# MSS_CTRL_MSS_CTRL_50D00000h register map
Vendor: Texas Instruments
Registers are 32-bit, read-write, reset values left out (the file's numbers can be read two ways) unless marked. A register's access mark holds for its fields unless they carry their own. Offsets are as the file gives them; [hi:lo] are bit positions; {n}, {i} and the like mark numbered series.

## MSS_CTRL (part 4 of 4)
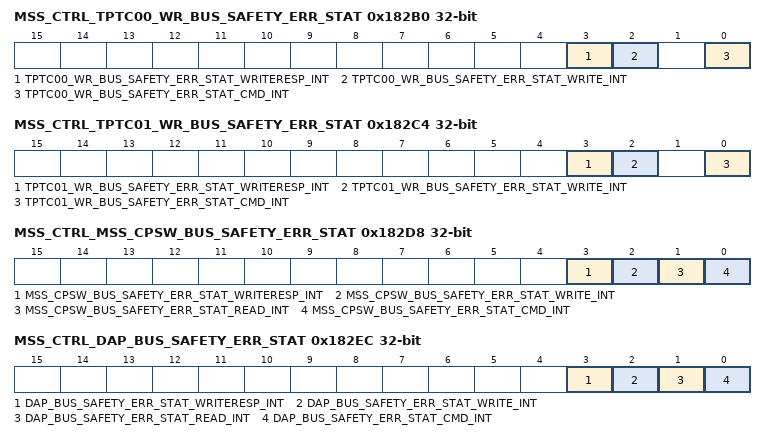
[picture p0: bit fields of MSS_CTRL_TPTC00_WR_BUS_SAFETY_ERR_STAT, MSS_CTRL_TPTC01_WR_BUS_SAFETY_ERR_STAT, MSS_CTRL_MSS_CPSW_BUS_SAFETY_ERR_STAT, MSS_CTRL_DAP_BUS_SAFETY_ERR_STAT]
0x182B0 MSS_CTRL_TPTC00_WR_BUS_SAFETY_ERR_STAT ro — This register Indicates the Error Syndrome of Command errors in Bus Safety Comparator of TPTC00_WR Initiator Port.
  [3] TPTC00_WR_BUS_SAFETY_ERR_STAT_WRITERESP_INT — Read this bitfield for comparator status for Write response bus from interconnect for this port. 1'b1 indicates error on Write Response Bus.
  [2] TPTC00_WR_BUS_SAFETY_ERR_STAT_WRITE_INT — Read this bitfield for comparator status for Write bus from interconnect for this port. 1'b1 at any bit indicates error on Write Bus
  [0] TPTC00_WR_BUS_SAFETY_ERR_STAT_CMD_INT — Read this bitfield for comparator status for command bus for this port. 1'b1 on any of the bits indicates an error on Command Bus
0x182C4 MSS_CTRL_TPTC01_WR_BUS_SAFETY_ERR_STAT ro — This register Indicates the Error Syndrome of Command errors in Bus Safety Comparator of TPTC01_WR Initiator Port.
  [3] TPTC01_WR_BUS_SAFETY_ERR_STAT_WRITERESP_INT — Read this bitfield for comparator status for Write response bus from interconnect for this port. 1'b1 indicates error on Write Response Bus.
  [2] TPTC01_WR_BUS_SAFETY_ERR_STAT_WRITE_INT — Read this bitfield for comparator status for Write bus from interconnect for this port. 1'b1 at any bit indicates error on Write Bus
  [0] TPTC01_WR_BUS_SAFETY_ERR_STAT_CMD_INT — Read this bitfield for comparator status for command bus for this port. 1'b1 on any of the bits indicates an error on Command Bus
0x182D8 MSS_CTRL_MSS_CPSW_BUS_SAFETY_ERR_STAT ro — This register Indicates the Error Syndrome of Command errors in Bus Safety Comparator of CPSW Initiator Port.
  [3] MSS_CPSW_BUS_SAFETY_ERR_STAT_WRITERESP_INT — Read this bitfield for comparator status for Write response bus from interconnect for this port. 1'b1 indicates error on Write Response Bus.
  [2] MSS_CPSW_BUS_SAFETY_ERR_STAT_WRITE_INT — Read this bitfield for comparator status for Write bus from interconnect for this port. 1'b1 at any bit indicates error on Write Bus
  [1] MSS_CPSW_BUS_SAFETY_ERR_STAT_READ_INT — Read this bitfield for comapartor status for read signals at this port. 1'b1 on any of the bits indicates an error on Read bus.
  [0] MSS_CPSW_BUS_SAFETY_ERR_STAT_CMD_INT — Read this bitfield for comparator status for command bus for this port. 1'b1 on any of the bits indicates an error on Command Bus
0x182EC MSS_CTRL_DAP_BUS_SAFETY_ERR_STAT ro — This register Indicates the Error Syndrome of Command errors in Bus Safety Comparator of DAP Initiator Port.
  [3] DAP_BUS_SAFETY_ERR_STAT_WRITERESP_INT — Read this bitfield for comparator status for Write response bus from interconnect for this port. 1'b1 indicates error on Write Response Bus.
  [2] DAP_BUS_SAFETY_ERR_STAT_WRITE_INT — Read this bitfield for comparator status for Write bus from interconnect for this port. 1'b1 at any bit indicates error on Write Bus
  [1] DAP_BUS_SAFETY_ERR_STAT_READ_INT — Read this bitfield for comapartor status for read signals at this port. 1'b1 on any of the bits indicates an error on Read bus.
  [0] DAP_BUS_SAFETY_ERR_STAT_CMD_INT — Read this bitfield for comparator status for command bus for this port. 1'b1 on any of the bits indicates an error on Command Bus
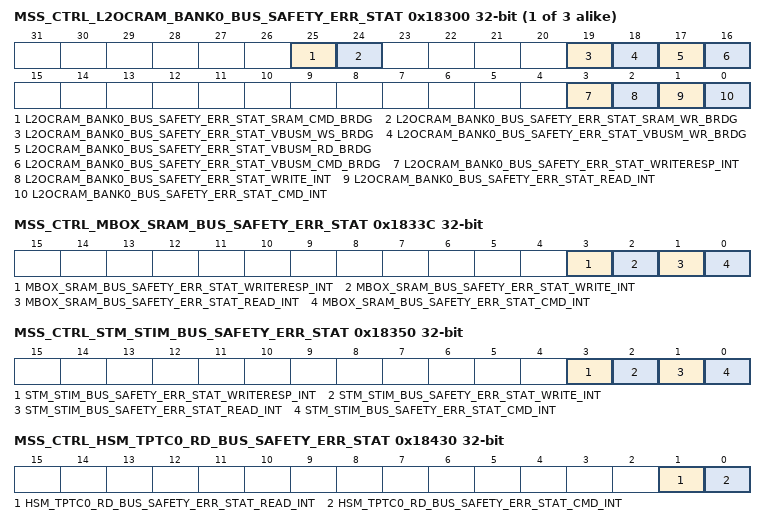
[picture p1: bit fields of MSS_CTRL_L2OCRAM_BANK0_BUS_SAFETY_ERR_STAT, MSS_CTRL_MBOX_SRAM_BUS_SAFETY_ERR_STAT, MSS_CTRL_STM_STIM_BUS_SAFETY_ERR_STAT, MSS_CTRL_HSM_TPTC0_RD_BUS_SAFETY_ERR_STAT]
{0x18300+0x14*i} MSS_CTRL_L2OCRAM_BANK{i}_BUS_SAFETY_ERR_STAT ro (i=0..2) — This register Indicates the Error Syndrome of Command errors in Bus Safety Comparator of L2 BANK{i} Target Port.
  [25] L2OCRAM_BANK{i}_BUS_SAFETY_ERR_STAT_SRAM_CMD_BRDG — Read this bitfield for comparator status for SRAM command bus from L2 RAM for this port. 1'b1 indicates error on command Bus.
  [24] L2OCRAM_BANK{i}_BUS_SAFETY_ERR_STAT_SRAM_WR_BRDG — Read this bitfield for comparator status for SRAM write bus from L2 RAM for this port. 1'b1 indicates error on Write Bus.
  [19] L2OCRAM_BANK{i}_BUS_SAFETY_ERR_STAT_VBUSM_WS_BRDG — Read this bitfield for comparator status for vbusm write bus from R5SS for this port. 1'b1 on any of the bits indicates an error on Write Bus
  [18] L2OCRAM_BANK{i}_BUS_SAFETY_ERR_STAT_VBUSM_WR_BRDG — Read this bitfield for comparator status for vbusm write bus from R5SS for this port. 1'b1 on any of the bits indicates an error on Write Bus
  [17] L2OCRAM_BANK{i}_BUS_SAFETY_ERR_STAT_VBUSM_RD_BRDG — Read this bitfield for comapartor status for vbusm read bus from R5SS at this port. 1'b1 on any of the bits indicates an error on Read bus.
  [16] L2OCRAM_BANK{i}_BUS_SAFETY_ERR_STAT_VBUSM_CMD_BRDG — Read this bitfield for comparator status for vbusm command bus from R5SS for this port. 1'b1 on any of the bits indicates an error on Command Bus
  [3] L2OCRAM_BANK{i}_BUS_SAFETY_ERR_STAT_WRITERESP_INT — Read this bitfield for comparator status for Write response bus from interconnect for this port. 1'b1 indicates error on Write Response Bus.
  [2] L2OCRAM_BANK{i}_BUS_SAFETY_ERR_STAT_WRITE_INT — Read this bitfield for comparator status for Write bus from interconnect for this port. 1'b1 at any bit indicates error on Write Bus
  [1] L2OCRAM_BANK{i}_BUS_SAFETY_ERR_STAT_READ_INT — Read this bitfield for comapartor status for read signals at this port. 1'b1 on any of the bits indicates an error on Read bus.
  [0] L2OCRAM_BANK{i}_BUS_SAFETY_ERR_STAT_CMD_INT — Read this bitfield for comparator status for command bus for this port. 1'b1 on any of the bits indicates an error on Command Bus
0x1833C MSS_CTRL_MBOX_SRAM_BUS_SAFETY_ERR_STAT ro — This register Indicates the Error Syndrome of Command errors in Bus Safety Comparator of MBOX SRAM Target Port.
  [3] MBOX_SRAM_BUS_SAFETY_ERR_STAT_WRITERESP_INT — Read this bitfield for comparator status for Write response bus from interconnect for this port. 1'b1 indicates error on Write Response Bus.
  [2] MBOX_SRAM_BUS_SAFETY_ERR_STAT_WRITE_INT — Read this bitfield for comparator status for Write bus from interconnect for this port. 1'b1 at any bit indicates error on Write Bus
  [1] MBOX_SRAM_BUS_SAFETY_ERR_STAT_READ_INT — Read this bitfield for comapartor status for read signals at this port. 1'b1 on any of the bits indicates an error on Read bus.
  [0] MBOX_SRAM_BUS_SAFETY_ERR_STAT_CMD_INT — Read this bitfield for comparator status for command bus for this port. 1'b1 on any of the bits indicates an error on Command Bus
0x18350 MSS_CTRL_STM_STIM_BUS_SAFETY_ERR_STAT ro — This register Indicates the Error Syndrome of Command errors in Bus Safety Comparator of STM Target Port.
  [3] STM_STIM_BUS_SAFETY_ERR_STAT_WRITERESP_INT — Read this bitfield for comparator status for Write response bus from interconnect for this port. 1'b1 indicates error on Write Response Bus.
  [2] STM_STIM_BUS_SAFETY_ERR_STAT_WRITE_INT — Read this bitfield for comparator status for Write bus from interconnect for this port. 1'b1 at any bit indicates error on Write Bus
  [1] STM_STIM_BUS_SAFETY_ERR_STAT_READ_INT — Read this bitfield for comapartor status for read signals at this port. 1'b1 on any of the bits indicates an error on Read bus.
  [0] STM_STIM_BUS_SAFETY_ERR_STAT_CMD_INT — Read this bitfield for comparator status for command bus for this port. 1'b1 on any of the bits indicates an error on Command Bus
0x18430 MSS_CTRL_HSM_TPTC0_RD_BUS_SAFETY_ERR_STAT ro — This register Indicates the Error Syndrome of Command errors in Bus Safety Comparator of HSM_TPTC0_RD Initiator Port.
  [1] HSM_TPTC0_RD_BUS_SAFETY_ERR_STAT_READ_INT — Read this bitfield for comapartor status for read signals at this port. 1'b1 on any of the bits indicates an error on Read bus.
  [0] HSM_TPTC0_RD_BUS_SAFETY_ERR_STAT_CMD_INT — Read this bitfield for comparator status for command bus for this port. 1'b1 on any of the bits indicates an error on Command Bus
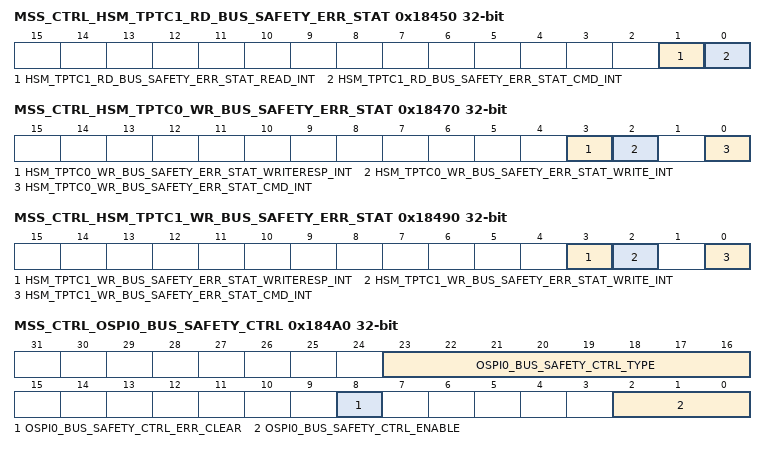
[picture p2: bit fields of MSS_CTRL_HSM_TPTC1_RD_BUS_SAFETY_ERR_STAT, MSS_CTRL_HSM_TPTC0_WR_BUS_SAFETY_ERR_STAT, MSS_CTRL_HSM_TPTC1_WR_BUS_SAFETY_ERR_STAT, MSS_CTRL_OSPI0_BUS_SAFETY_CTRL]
0x18450 MSS_CTRL_HSM_TPTC1_RD_BUS_SAFETY_ERR_STAT ro — This register Indicates the Error Syndrome of Command errors in Bus Safety Comparator of HSM_TPTC1_RD Initiator Port.
  [1] HSM_TPTC1_RD_BUS_SAFETY_ERR_STAT_READ_INT — Read this bitfield for comapartor status for read signals at this port. 1'b1 on any of the bits indicates an error on Read bus.
  [0] HSM_TPTC1_RD_BUS_SAFETY_ERR_STAT_CMD_INT — Read this bitfield for comparator status for command bus for this port. 1'b1 on any of the bits indicates an error on Command Bus
0x18470 MSS_CTRL_HSM_TPTC0_WR_BUS_SAFETY_ERR_STAT ro — This register Indicates the Error Syndrome of Command errors in Bus Safety Comparator of HSM_TPTC0_WR Initiator Port.
  [3] HSM_TPTC0_WR_BUS_SAFETY_ERR_STAT_WRITERESP_INT — Read this bitfield for comparator status for Write response bus from interconnect for this port. 1'b1 indicates error on Write Response Bus.
  [2] HSM_TPTC0_WR_BUS_SAFETY_ERR_STAT_WRITE_INT — Read this bitfield for comparator status for Write bus from interconnect for this port. 1'b1 at any bit indicates error on Write Bus
  [0] HSM_TPTC0_WR_BUS_SAFETY_ERR_STAT_CMD_INT — Read this bitfield for comparator status for command bus for this port. 1'b1 on any of the bits indicates an error on Command Bus
0x18490 MSS_CTRL_HSM_TPTC1_WR_BUS_SAFETY_ERR_STAT ro — This register Indicates the Error Syndrome of Command errors in Bus Safety Comparator of HSM_TPTC1_WR Initiator Port.
  [3] HSM_TPTC1_WR_BUS_SAFETY_ERR_STAT_WRITERESP_INT — Read this bitfield for comparator status for Write response bus from interconnect for this port. 1'b1 indicates error on Write Response Bus.
  [2] HSM_TPTC1_WR_BUS_SAFETY_ERR_STAT_WRITE_INT — Read this bitfield for comparator status for Write bus from interconnect for this port. 1'b1 at any bit indicates error on Write Bus
  [0] HSM_TPTC1_WR_BUS_SAFETY_ERR_STAT_CMD_INT — Read this bitfield for comparator status for command bus for this port. 1'b1 on any of the bits indicates an error on Command Bus
0x184A0 MSS_CTRL_OSPI0_BUS_SAFETY_CTRL access per field — This register is used to Control and Configure the Interconnect Safety Behaviour of OSPI Target Port.
  [23:16] OSPI0_BUS_SAFETY_CTRL_TYPE ro — This bitfield gives a top level idea of the available bus [cmd,wr,ws,rd] for the particular Target/Initiator and whether it follows the VBUS protocol or not. Bit 0 - 1'b1 indicates the Command bus is implemented to this target/initiator else it is set to 1'b0. Bit 1 - 1'b1 indicates the write bus is implemented to this target/initiator else it is set to 1'b0. Bit 2 - 1'b1 indicates the write status bus is implemented to this target/initiator else it is set to 1'b0. Bit 3 - 1'b1 indicates the read bus is implemented to this target/initiator else it is set to 1'b0. Bit 4 - 1'b0 indicates the port follows the VBUS protocol else it is set to 1'b1. Bits 5-7 are set to 3'b000.
  [8] OSPI0_BUS_SAFETY_CTRL_ERR_CLEAR rw — Set this bit to 1'b1 to clear the error status for this port
  [2:0] OSPI0_BUS_SAFETY_CTRL_ENABLE rw — Set this bit to 3'b111 to enable the safety configuration for this port. Set this bit to 3'b000 to disable the safety configuration for this port.
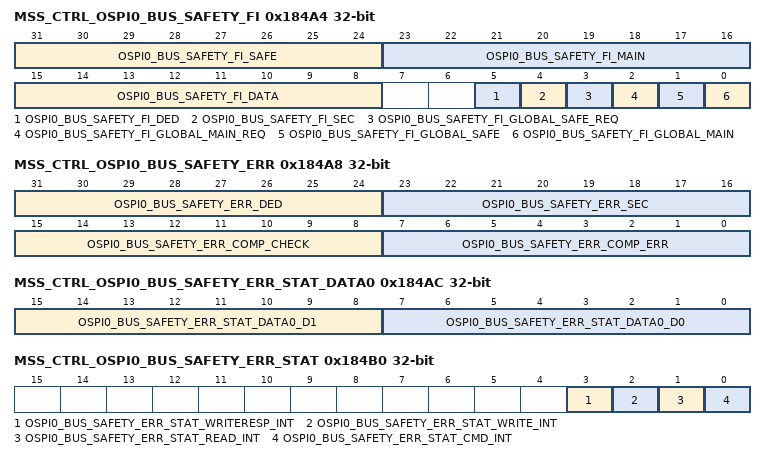
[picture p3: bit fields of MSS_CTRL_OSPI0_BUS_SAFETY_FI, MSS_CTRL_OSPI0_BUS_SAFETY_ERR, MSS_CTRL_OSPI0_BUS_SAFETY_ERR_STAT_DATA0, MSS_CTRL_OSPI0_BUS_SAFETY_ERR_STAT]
0x184A4 MSS_CTRL_OSPI0_BUS_SAFETY_FI — This register is used to Inject fault on the Interconnect Safety comparator of OSPI Target Port.
  [31:24] OSPI0_BUS_SAFETY_FI_SAFE — This bitfield is used to inject fault on Read, write, command and request bus on the safe Interconnect. Bit 0 - Set this bit to inject fault on the Command bus. Bit 1 - Set this bit to inject fault on theWrite bus. Bit 2 - Set this bit to inject fault on the Write Status bus.Bit 3 - Set this bit to inject fault on the Read bus. Bit 7- Set this bit to inject fault on the corresponding request bus.
  [23:16] OSPI0_BUS_SAFETY_FI_MAIN — This bitfield is used to inject fault on Read, write, command and request bus on the main Interconnect.Bit 0 - Set this bit to inject fault on the Command bus. Bit 1 - Set this bit to inject fault on theWrite bus. Bit 2 - Set this bit to inject fault on the Write Status bus.Bit 3 - Set this bit to inject fault on the Read bus. Bit 7- Set this bit to inject fault on the corresponding request bus.
  [15:8] OSPI0_BUS_SAFETY_FI_DATA — Set bit 0 to 1'b1 to inject sec and ded faults on [31:0] bits of data bus.Set bit 1 to 1'b1 to inject sec and ded faults on [64:32] bits of data bus.
  [5] OSPI0_BUS_SAFETY_FI_DED — Set this bit to 1'b1 inject ded error on data at this port
  [4] OSPI0_BUS_SAFETY_FI_SEC — Set this bit to 1'b1 to inject sec error on data at this port
  [3] OSPI0_BUS_SAFETY_FI_GLOBAL_SAFE_REQ — Set this bit 1'b1 to inject fault for request signals on Safe Interconnect. This is enabled only when the 7th bit of safe bitfield of this register and particular bit coressponding to this port on the safe bitfield of this register is set HIGH
  [2] OSPI0_BUS_SAFETY_FI_GLOBAL_MAIN_REQ — Set this bit to 1'b1 to inject fault for request signals on main Interconnect. This is enabled only when the 7th bit of main bitfield of this register and particular bit coressponding to this port on the main bitfield of this register is set HIGH
  [1] OSPI0_BUS_SAFETY_FI_GLOBAL_SAFE — This is a global safe Fault injection signal. Set this bit to inject fault on all the safety buses of the safe interconnect except req signal. Writing a 1'b1 injects fault on interconnect.
  [0] OSPI0_BUS_SAFETY_FI_GLOBAL_MAIN — This is a global main Fault injection signal. Set this bit to inject fault on all the buses of the main interconnect except req signal. Writing a 1'b1 injects fault on interconnect.
0x184A8 MSS_CTRL_OSPI0_BUS_SAFETY_ERR ro — This Register provides the Error Status of Bus Safety Comparator of OSPI Target Port.
  [31:24] OSPI0_BUS_SAFETY_ERR_DED — This flag signals detection of dual error in Data at this port.Flag is generted for 32 bit segment of Data BusBit 0 - 1'b1 indicates ded on [31:0] bit of Data busBit 1 - 1'b1 indicates ded on [63:32] bit of Data busBit [7:2] - Unused. Set to 1'b0
  [23:16] OSPI0_BUS_SAFETY_ERR_SEC — This flag signals detection of single error in Data at this port. Flag is generted for 32 bit segment of Data BusBit 0 - 1'b1 indicates sec on [31:0] bit of Data busBit 1 - 1'b1 indicates sec on [63:32] bit of Data busBit [7:2] - Unused. Set to 1'b0
  [15:8] OSPI0_BUS_SAFETY_ERR_COMP_CHECK — This is used to verify the proper functioning of fault Injection on all the buses.1'b1 indicates error in the corresponding Bus has been injected successfully. Bit 0 - This is a Bitwise AND of error compares of all command bus signals.Bit 1 - This is a Bitwise AND of error compares of all write bus signals.Bit 2 - This is a Bitwise AND of error compares of all write status bus signals.Bit 3 - This is a Bitwise AND of error compares of all read bus signals.Bits [7:4] are unused.
  [7:0] OSPI0_BUS_SAFETY_ERR_COMP_ERR — 1'b1 indicates error in the corresponding Bus whenever a fault is detected at any bus signalBit 0 - This is a Bitwise OR of error compares of all command bus signals.Bit 1 - This is a Bitwise OR of error compares of all write bus signals.Bit 2 - This is a Bitwise OR of error compares of all write status bus signals.Bit 3 - This is a Bitwise OR of error compares of all read bus signals.Bits [7:4] are unused.
0x184AC MSS_CTRL_OSPI0_BUS_SAFETY_ERR_STAT_DATA0 ro — This register Indicates the Error Syndrome of Data errors in Bus Safety Comparator of OSPI Target Port.
  [15:8] OSPI0_BUS_SAFETY_ERR_STAT_DATA0_D1 — Read this bitfield for Comparator status for Higher 32 bits [63:32] of data bus at this port. It represent the position of the flipped bit in case of SEC.
  [7:0] OSPI0_BUS_SAFETY_ERR_STAT_DATA0_D0 — Read this bitfield for Comparator status for lower 32 bits [31:0] of data bus at this port. It represent the position of the flipped bit in case of SEC.
0x184B0 MSS_CTRL_OSPI0_BUS_SAFETY_ERR_STAT ro — This register Indicates the Error Syndrome of Command errors in Bus Safety Comparator of OSPI Target Port.
  [3] OSPI0_BUS_SAFETY_ERR_STAT_WRITERESP_INT — Read this bitfield for comparator status for Write response bus from interconnect for this port. 1'b1 indicates error on Write Response Bus.
  [2] OSPI0_BUS_SAFETY_ERR_STAT_WRITE_INT — Read this bitfield for comparator status for Write bus from interconnect for this port. 1'b1 at any bit indicates error on Write Bus
  [1] OSPI0_BUS_SAFETY_ERR_STAT_READ_INT — Read this bitfield for comapartor status for read signals at this port. 1'b1 on any of the bits indicates an error on Read bus.
  [0] OSPI0_BUS_SAFETY_ERR_STAT_CMD_INT — Read this bitfield for comparator status for command bus for this port. 1'b1 on any of the bits indicates an error on Command Bus
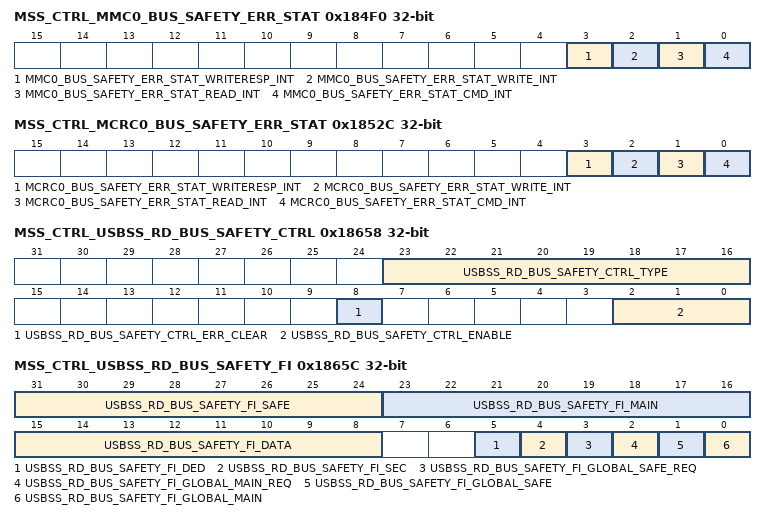
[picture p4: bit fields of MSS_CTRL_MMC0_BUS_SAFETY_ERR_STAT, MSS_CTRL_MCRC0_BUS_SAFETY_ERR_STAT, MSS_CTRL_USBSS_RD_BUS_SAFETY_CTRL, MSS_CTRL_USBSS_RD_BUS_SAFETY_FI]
0x184F0 MSS_CTRL_MMC0_BUS_SAFETY_ERR_STAT ro — This register Indicates the Error Syndrome of Command errors in Bus Safety Comparator of MMC0 Target Port.
  [3] MMC0_BUS_SAFETY_ERR_STAT_WRITERESP_INT — Read this bitfield for comparator status for Write response bus from interconnect for this port. 1'b1 indicates error on Write Response Bus.
  [2] MMC0_BUS_SAFETY_ERR_STAT_WRITE_INT — Read this bitfield for comparator status for Write bus from interconnect for this port. 1'b1 at any bit indicates error on Write Bus
  [1] MMC0_BUS_SAFETY_ERR_STAT_READ_INT — Read this bitfield for comapartor status for read signals at this port. 1'b1 on any of the bits indicates an error on Read bus.
  [0] MMC0_BUS_SAFETY_ERR_STAT_CMD_INT — Read this bitfield for comparator status for command bus for this port. 1'b1 on any of the bits indicates an error on Command Bus
0x1852C MSS_CTRL_MCRC0_BUS_SAFETY_ERR_STAT ro — This register Indicates the Error Syndrome of Command errors in Bus Safety Comparator of MCRC Target Port.
  [3] MCRC0_BUS_SAFETY_ERR_STAT_WRITERESP_INT — Read this bitfield for comparator status for Write response bus from interconnect for this port. 1'b1 indicates error on Write Response Bus.
  [2] MCRC0_BUS_SAFETY_ERR_STAT_WRITE_INT — Read this bitfield for comparator status for Write bus from interconnect for this port. 1'b1 at any bit indicates error on Write Bus
  [1] MCRC0_BUS_SAFETY_ERR_STAT_READ_INT — Read this bitfield for comapartor status for read signals at this port. 1'b1 on any of the bits indicates an error on Read bus.
  [0] MCRC0_BUS_SAFETY_ERR_STAT_CMD_INT — Read this bitfield for comparator status for command bus for this port. 1'b1 on any of the bits indicates an error on Command Bus
0x18658 MSS_CTRL_USBSS_RD_BUS_SAFETY_CTRL access per field — This register is used to Control and Configure the Interconnect Safety Behaviour of USBSS_RD Target Port.
  [23:16] USBSS_RD_BUS_SAFETY_CTRL_TYPE ro — This bitfield gives a top level idea of the available bus [cmd,wr,ws,rd] for the particular Target/Initiator and whether it follows the VBUS protocol or not. Bit 0 - 1'b1 indicates the Command bus is implemented to this target/initiator else it is set to 1'b0. Bit 1 - 1'b1 indicates the write bus is implemented to this target/initiator else it is set to 1'b0. Bit 2 - 1'b1 indicates the write status bus is implemented to this target/initiator else it is set to 1'b0. Bit 3 - 1'b1 indicates the read bus is implemented to this target/initiator else it is set to 1'b0. Bit 4 - 1'b0 indicates the port follows the VBUS protocol else it is set to 1'b1. Bits 5-7 are set to 3'b000.
  [8] USBSS_RD_BUS_SAFETY_CTRL_ERR_CLEAR rw — Set this bit to 1'b1 to clear the error status for this port
  [2:0] USBSS_RD_BUS_SAFETY_CTRL_ENABLE rw — Set this bit to 3'b111 to enable the safety configuration for this port. Set this bit to 3'b000 to disable the safety configuration for this port.
0x1865C MSS_CTRL_USBSS_RD_BUS_SAFETY_FI — This register is used to Inject fault on the Interconnect Safety comparator of USBSS RD Target Port.
  [31:24] USBSS_RD_BUS_SAFETY_FI_SAFE — This bitfield is used to inject fault on Read, write, command and request bus on the safe Interconnect. Bit 0 - Set this bit to inject fault on the Command bus. Bit 1 - Set this bit to inject fault on theWrite bus. Bit 2 - Set this bit to inject fault on the Write Status bus.Bit 3 - Set this bit to inject fault on the Read bus. Bit 7- Set this bit to inject fault on the corresponding request bus.
  [23:16] USBSS_RD_BUS_SAFETY_FI_MAIN — This bitfield is used to inject fault on Read, write, command and request bus on the main Interconnect.Bit 0 - Set this bit to inject fault on the Command bus. Bit 1 - Set this bit to inject fault on theWrite bus. Bit 2 - Set this bit to inject fault on the Write Status bus.Bit 3 - Set this bit to inject fault on the Read bus. Bit 7- Set this bit to inject fault on the corresponding request bus.
  [15:8] USBSS_RD_BUS_SAFETY_FI_DATA — Set bit 0 to 1'b1 to inject sec and ded faults on [31:0] bits of data bus.Set bit 1 to 1'b1 to inject sec and ded faults on [64:32] bits of data bus.
  [5] USBSS_RD_BUS_SAFETY_FI_DED — Set this bit to 1'b1 inject ded error on data at this port
  [4] USBSS_RD_BUS_SAFETY_FI_SEC — Set this bit to 1'b1 to inject sec error on data at this port
  [3] USBSS_RD_BUS_SAFETY_FI_GLOBAL_SAFE_REQ — Set this bit 1'b1 to inject fault for request signals on Safe Interconnect. This is enabled only when the 7th bit of safe bitfield of this register and particular bit coressponding to this port on the safe bitfield of this register is set HIGH
  [2] USBSS_RD_BUS_SAFETY_FI_GLOBAL_MAIN_REQ — Set this bit to 1'b1 to inject fault for request signals on main Interconnect. This is enabled only when the 7th bit of main bitfield of this register and particular bit coressponding to this port on the main bitfield of this register is set HIGH
  [1] USBSS_RD_BUS_SAFETY_FI_GLOBAL_SAFE — This is a global safe Fault injection signal. Set this bit to inject fault on all the safety buses of the safe interconnect except req signal. Writing a 1'b1 injects fault on interconnect.
  [0] USBSS_RD_BUS_SAFETY_FI_GLOBAL_MAIN — This is a global main Fault injection signal. Set this bit to inject fault on all the buses of the main interconnect except req signal. Writing a 1'b1 injects fault on interconnect.
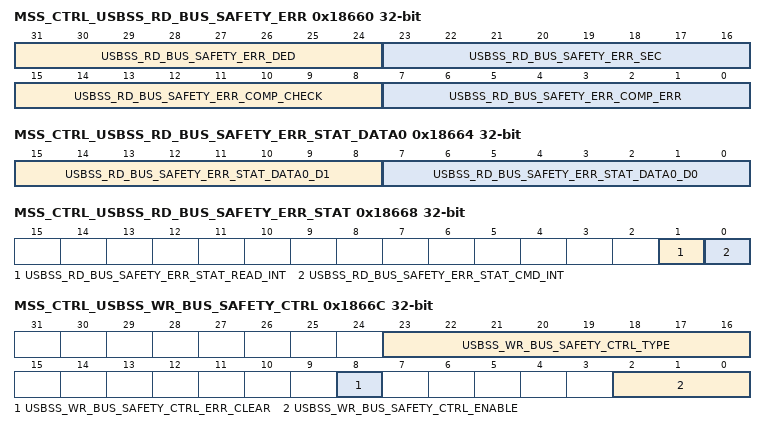
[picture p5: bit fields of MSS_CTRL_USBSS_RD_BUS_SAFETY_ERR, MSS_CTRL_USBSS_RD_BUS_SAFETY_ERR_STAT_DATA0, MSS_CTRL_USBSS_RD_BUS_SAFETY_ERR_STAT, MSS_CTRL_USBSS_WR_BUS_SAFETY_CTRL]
0x18660 MSS_CTRL_USBSS_RD_BUS_SAFETY_ERR ro — This Register provides the Error Status of Bus Safety Comparator of USBSS RD Target Port.
  [31:24] USBSS_RD_BUS_SAFETY_ERR_DED — This flag signals detection of dual error in Data at this port.Flag is generted for 32 bit segment of Data BusBit 0 - 1'b1 indicates ded on [31:0] bit of Data busBit 1 - 1'b1 indicates ded on [63:32] bit of Data busBit [7:2] - Unused. Set to 1'b0
  [23:16] USBSS_RD_BUS_SAFETY_ERR_SEC — This flag signals detection of single error in Data at this port. Flag is generted for 32 bit segment of Data BusBit 0 - 1'b1 indicates sec on [31:0] bit of Data busBit 1 - 1'b1 indicates sec on [63:32] bit of Data busBit [7:2] - Unused. Set to 1'b0
  [15:8] USBSS_RD_BUS_SAFETY_ERR_COMP_CHECK — This is used to verify the proper functioning of fault Injection on all the buses.1'b1 indicates error in the corresponding Bus has been injected successfully. Bit 0 - This is a Bitwise AND of error compares of all command bus signals.Bit 1 - This is a Bitwise AND of error compares of all write bus signals.Bit 2 - This is a Bitwise AND of error compares of all write status bus signals.Bit 3 - This is a Bitwise AND of error compares of all read bus signals.Bits [7:4] are unused.
  [7:0] USBSS_RD_BUS_SAFETY_ERR_COMP_ERR — 1'b1 indicates error in the corresponding Bus whenever a fault is detected at any bus signalBit 0 - This is a Bitwise OR of error compares of all command bus signals.Bit 1 - This is a Bitwise OR of error compares of all write bus signals.Bit 2 - This is a Bitwise OR of error compares of all write status bus signals.Bit 3 - This is a Bitwise OR of error compares of all read bus signals.Bits [7:4] are unused.
0x18664 MSS_CTRL_USBSS_RD_BUS_SAFETY_ERR_STAT_DATA0 ro — This register Indicates the Error Syndrome of Data errors in Bus Safety Comparator of USBSS RD Target Port.
  [15:8] USBSS_RD_BUS_SAFETY_ERR_STAT_DATA0_D1 — Read this bitfield for Comparator status for Higher 32 bits [63:32] of data bus at this port. It represent the position of the flipped bit in case of SEC.
  [7:0] USBSS_RD_BUS_SAFETY_ERR_STAT_DATA0_D0 — Read this bitfield for Comparator status for lower 32 bits [31:0] of data bus at this port. It represent the position of the flipped bit in case of SEC.
0x18668 MSS_CTRL_USBSS_RD_BUS_SAFETY_ERR_STAT ro — This register Indicates the Error Syndrome of Command errors in Bus Safety Comparator of USBSS RD Target Port.
  [1] USBSS_RD_BUS_SAFETY_ERR_STAT_READ_INT — Read this bitfield for comapartor status for read signals at this port. 1'b1 on any of the bits indicates an error on Read bus.
  [0] USBSS_RD_BUS_SAFETY_ERR_STAT_CMD_INT — Read this bitfield for comparator status for command bus for this port. 1'b1 on any of the bits indicates an error on Command Bus
0x1866C MSS_CTRL_USBSS_WR_BUS_SAFETY_CTRL access per field — This register is used to Control and Configure the Interconnect Safety Behaviour of USBSS_WR Target Port.
  [23:16] USBSS_WR_BUS_SAFETY_CTRL_TYPE ro — This bitfield gives a top level idea of the available bus [cmd,wr,ws,rd] for the particular Target/Initiator and whether it follows the VBUS protocol or not. Bit 0 - 1'b1 indicates the Command bus is implemented to this target/initiator else it is set to 1'b0. Bit 1 - 1'b1 indicates the write bus is implemented to this target/initiator else it is set to 1'b0. Bit 2 - 1'b1 indicates the write status bus is implemented to this target/initiator else it is set to 1'b0. Bit 3 - 1'b1 indicates the read bus is implemented to this target/initiator else it is set to 1'b0. Bit 4 - 1'b0 indicates the port follows the VBUS protocol else it is set to 1'b1. Bits 5-7 are set to 3'b000.
  [8] USBSS_WR_BUS_SAFETY_CTRL_ERR_CLEAR rw — Set this bit to 1'b1 to clear the error status for this port
  [2:0] USBSS_WR_BUS_SAFETY_CTRL_ENABLE rw — Set this bit to 3'b111 to enable the safety configuration for this port. Set this bit to 3'b000 to disable the safety configuration for this port.
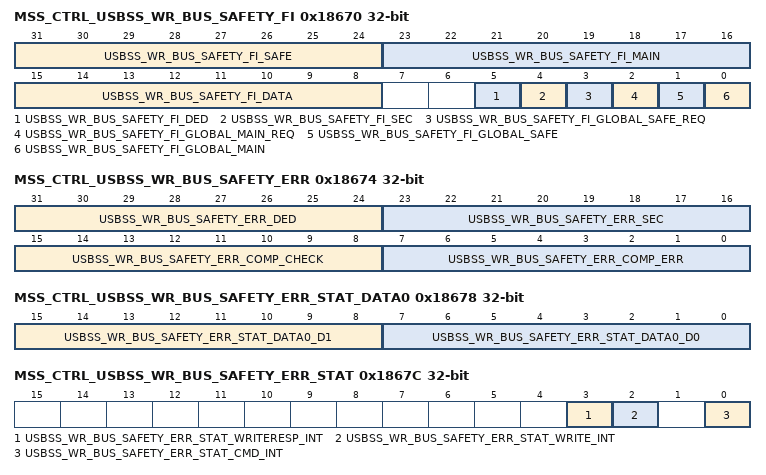
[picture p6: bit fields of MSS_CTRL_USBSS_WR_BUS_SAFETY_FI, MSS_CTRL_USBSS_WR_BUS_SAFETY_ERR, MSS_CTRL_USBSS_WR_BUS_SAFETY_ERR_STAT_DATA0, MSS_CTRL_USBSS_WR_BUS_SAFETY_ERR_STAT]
0x18670 MSS_CTRL_USBSS_WR_BUS_SAFETY_FI — This register is used to Inject fault on the Interconnect Safety comparator of USBSS WR Target Port.
  [31:24] USBSS_WR_BUS_SAFETY_FI_SAFE — This bitfield is used to inject fault on Read, write, command and request bus on the safe Interconnect. Bit 0 - Set this bit to inject fault on the Command bus. Bit 1 - Set this bit to inject fault on theWrite bus. Bit 2 - Set this bit to inject fault on the Write Status bus.Bit 3 - Set this bit to inject fault on the Read bus. Bit 7- Set this bit to inject fault on the corresponding request bus.
  [23:16] USBSS_WR_BUS_SAFETY_FI_MAIN — This bitfield is used to inject fault on Read, write, command and request bus on the main Interconnect.Bit 0 - Set this bit to inject fault on the Command bus. Bit 1 - Set this bit to inject fault on theWrite bus. Bit 2 - Set this bit to inject fault on the Write Status bus.Bit 3 - Set this bit to inject fault on the Read bus. Bit 7- Set this bit to inject fault on the corresponding request bus.
  [15:8] USBSS_WR_BUS_SAFETY_FI_DATA — Set bit 0 to 1'b1 to inject sec and ded faults on [31:0] bits of data bus.Set bit 1 to 1'b1 to inject sec and ded faults on [64:32] bits of data bus.
  [5] USBSS_WR_BUS_SAFETY_FI_DED — Set this bit to 1'b1 inject ded error on data at this port
  [4] USBSS_WR_BUS_SAFETY_FI_SEC — Set this bit to 1'b1 to inject sec error on data at this port
  [3] USBSS_WR_BUS_SAFETY_FI_GLOBAL_SAFE_REQ — Set this bit 1'b1 to inject fault for request signals on Safe Interconnect. This is enabled only when the 7th bit of safe bitfield of this register and particular bit coressponding to this port on the safe bitfield of this register is set HIGH
  [2] USBSS_WR_BUS_SAFETY_FI_GLOBAL_MAIN_REQ — Set this bit to 1'b1 to inject fault for request signals on main Interconnect. This is enabled only when the 7th bit of main bitfield of this register and particular bit coressponding to this port on the main bitfield of this register is set HIGH
  [1] USBSS_WR_BUS_SAFETY_FI_GLOBAL_SAFE — This is a global safe Fault injection signal. Set this bit to inject fault on all the safety buses of the safe interconnect except req signal. Writing a 1'b1 injects fault on interconnect.
  [0] USBSS_WR_BUS_SAFETY_FI_GLOBAL_MAIN — This is a global main Fault injection signal. Set this bit to inject fault on all the buses of the main interconnect except req signal. Writing a 1'b1 injects fault on interconnect.
0x18674 MSS_CTRL_USBSS_WR_BUS_SAFETY_ERR ro — This Register provides the Error Status of Bus Safety Comparator of USBSS WR Target Port.
  [31:24] USBSS_WR_BUS_SAFETY_ERR_DED — This flag signals detection of dual error in Data at this port.Flag is generted for 32 bit segment of Data BusBit 0 - 1'b1 indicates ded on [31:0] bit of Data busBit 1 - 1'b1 indicates ded on [63:32] bit of Data busBit [7:2] - Unused. Set to 1'b0
  [23:16] USBSS_WR_BUS_SAFETY_ERR_SEC — This flag signals detection of single error in Data at this port. Flag is generted for 32 bit segment of Data BusBit 0 - 1'b1 indicates sec on [31:0] bit of Data busBit 1 - 1'b1 indicates sec on [63:32] bit of Data busBit [7:2] - Unused. Set to 1'b0
  [15:8] USBSS_WR_BUS_SAFETY_ERR_COMP_CHECK — This is used to verify the proper functioning of fault Injection on all the buses.1'b1 indicates error in the corresponding Bus has been injected successfully. Bit 0 - This is a Bitwise AND of error compares of all command bus signals.Bit 1 - This is a Bitwise AND of error compares of all write bus signals.Bit 2 - This is a Bitwise AND of error compares of all write status bus signals.Bit 3 - This is a Bitwise AND of error compares of all read bus signals.Bits [7:4] are unused.
  [7:0] USBSS_WR_BUS_SAFETY_ERR_COMP_ERR — 1'b1 indicates error in the corresponding Bus whenever a fault is detected at any bus signalBit 0 - This is a Bitwise OR of error compares of all command bus signals.Bit 1 - This is a Bitwise OR of error compares of all write bus signals.Bit 2 - This is a Bitwise OR of error compares of all write status bus signals.Bit 3 - This is a Bitwise OR of error compares of all read bus signals.Bits [7:4] are unused.
0x18678 MSS_CTRL_USBSS_WR_BUS_SAFETY_ERR_STAT_DATA0 ro — This register Indicates the Error Syndrome of Data errors in Bus Safety Comparator of USBSS WR Target Port.
  [15:8] USBSS_WR_BUS_SAFETY_ERR_STAT_DATA0_D1 — Read this bitfield for Comparator status for Higher 32 bits [63:32] of data bus at this port. It represent the position of the flipped bit in case of SEC.
  [7:0] USBSS_WR_BUS_SAFETY_ERR_STAT_DATA0_D0 — Read this bitfield for Comparator status for lower 32 bits [31:0] of data bus at this port. It represent the position of the flipped bit in case of SEC.
0x1867C MSS_CTRL_USBSS_WR_BUS_SAFETY_ERR_STAT ro — This register Indicates the Error Syndrome of Command errors in Bus Safety Comparator of USBSS WR Target Port.
  [3] USBSS_WR_BUS_SAFETY_ERR_STAT_WRITERESP_INT — Read this bitfield for comparator status for Write response bus from interconnect for this port. 1'b1 indicates error on Write Response Bus.
  [2] USBSS_WR_BUS_SAFETY_ERR_STAT_WRITE_INT — Read this bitfield for comparator status for Write bus from interconnect for this port. 1'b1 at any bit indicates error on Write Bus
  [0] USBSS_WR_BUS_SAFETY_ERR_STAT_CMD_INT — Read this bitfield for comparator status for command bus for this port. 1'b1 on any of the bits indicates an error on Command Bus
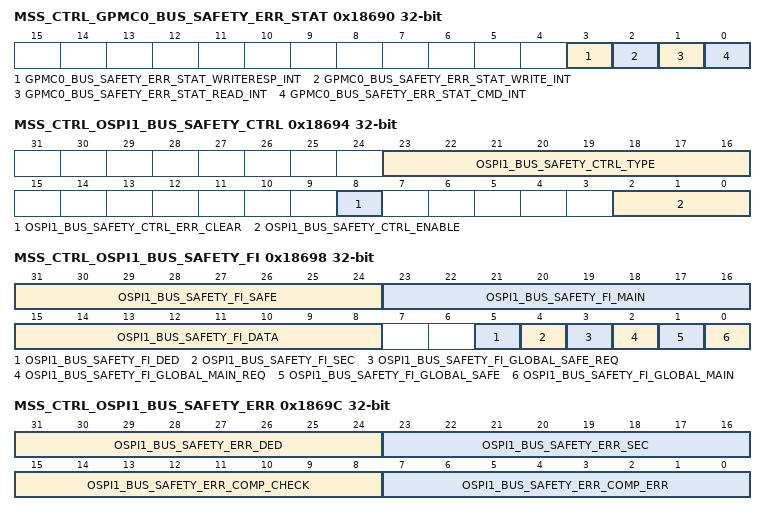
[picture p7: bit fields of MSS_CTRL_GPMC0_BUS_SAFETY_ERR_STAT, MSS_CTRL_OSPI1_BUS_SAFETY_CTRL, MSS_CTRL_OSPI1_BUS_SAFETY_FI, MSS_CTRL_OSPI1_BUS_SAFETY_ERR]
0x18690 MSS_CTRL_GPMC0_BUS_SAFETY_ERR_STAT ro — This register Indicates the Error Syndrome of Command errors in Bus Safety Comparator of GPMC0 Target Port.
  [3] GPMC0_BUS_SAFETY_ERR_STAT_WRITERESP_INT — Read this bitfield for comparator status for Write response bus from interconnect for this port. 1'b1 indicates error on Write Response Bus.
  [2] GPMC0_BUS_SAFETY_ERR_STAT_WRITE_INT — Read this bitfield for comparator status for Write bus from interconnect for this port. 1'b1 at any bit indicates error on Write Bus
  [1] GPMC0_BUS_SAFETY_ERR_STAT_READ_INT — Read this bitfield for comapartor status for read signals at this port. 1'b1 on any of the bits indicates an error on Read bus.
  [0] GPMC0_BUS_SAFETY_ERR_STAT_CMD_INT — Read this bitfield for comparator status for command bus for this port. 1'b1 on any of the bits indicates an error on Command Bus
0x18694 MSS_CTRL_OSPI1_BUS_SAFETY_CTRL access per field — This register is used to Control and Configure the Interconnect Safety Behaviour of OSPI1 Target Port.
  [23:16] OSPI1_BUS_SAFETY_CTRL_TYPE ro — This bitfield gives a top level idea of the available bus [cmd,wr,ws,rd] for the particular Target/Initiator and whether it follows the VBUS protocol or not. Bit 0 - 1'b1 indicates the Command bus is implemented to this target/initiator else it is set to 1'b0. Bit 1 - 1'b1 indicates the write bus is implemented to this target/initiator else it is set to 1'b0. Bit 2 - 1'b1 indicates the write status bus is implemented to this target/initiator else it is set to 1'b0. Bit 3 - 1'b1 indicates the read bus is implemented to this target/initiator else it is set to 1'b0. Bit 4 - 1'b0 indicates the port follows the VBUS protocol else it is set to 1'b1. Bits 5-7 are set to 3'b000.
  [8] OSPI1_BUS_SAFETY_CTRL_ERR_CLEAR rw — Set this bit to 1'b1 to clear the error status for this port
  [2:0] OSPI1_BUS_SAFETY_CTRL_ENABLE rw — Set this bit to 3'b111 to enable the safety configuration for this port. Set this bit to 3'b000 to disable the safety configuration for this port.
0x18698 MSS_CTRL_OSPI1_BUS_SAFETY_FI — This register is used to Inject fault on the Interconnect Safety comparator of OSPI1 Target Port.
  [31:24] OSPI1_BUS_SAFETY_FI_SAFE — This bitfield is used to inject fault on Read, write, command and request bus on the safe Interconnect. Bit 0 - Set this bit to inject fault on the Command bus. Bit 1 - Set this bit to inject fault on theWrite bus. Bit 2 - Set this bit to inject fault on the Write Status bus.Bit 3 - Set this bit to inject fault on the Read bus. Bit 7- Set this bit to inject fault on the corresponding request bus.
  [23:16] OSPI1_BUS_SAFETY_FI_MAIN — This bitfield is used to inject fault on Read, write, command and request bus on the main Interconnect.Bit 0 - Set this bit to inject fault on the Command bus. Bit 1 - Set this bit to inject fault on theWrite bus. Bit 2 - Set this bit to inject fault on the Write Status bus.Bit 3 - Set this bit to inject fault on the Read bus. Bit 7- Set this bit to inject fault on the corresponding request bus.
  [15:8] OSPI1_BUS_SAFETY_FI_DATA — Set bit 0 to 1'b1 to inject sec and ded faults on [31:0] bits of data bus.Set bit 1 to 1'b1 to inject sec and ded faults on [64:32] bits of data bus.
  [5] OSPI1_BUS_SAFETY_FI_DED — Set this bit to 1'b1 inject ded error on data at this port
  [4] OSPI1_BUS_SAFETY_FI_SEC — Set this bit to 1'b1 to inject sec error on data at this port
  [3] OSPI1_BUS_SAFETY_FI_GLOBAL_SAFE_REQ — Set this bit 1'b1 to inject fault for request signals on Safe Interconnect. This is enabled only when the 7th bit of safe bitfield of this register and particular bit coressponding to this port on the safe bitfield of this register is set HIGH
  [2] OSPI1_BUS_SAFETY_FI_GLOBAL_MAIN_REQ — Set this bit to 1'b1 to inject fault for request signals on main Interconnect. This is enabled only when the 7th bit of main bitfield of this register and particular bit coressponding to this port on the main bitfield of this register is set HIGH
  [1] OSPI1_BUS_SAFETY_FI_GLOBAL_SAFE — This is a global safe Fault injection signal. Set this bit to inject fault on all the safety buses of the safe interconnect except req signal. Writing a 1'b1 injects fault on interconnect.
  [0] OSPI1_BUS_SAFETY_FI_GLOBAL_MAIN — This is a global main Fault injection signal. Set this bit to inject fault on all the buses of the main interconnect except req signal. Writing a 1'b1 injects fault on interconnect.
0x1869C MSS_CTRL_OSPI1_BUS_SAFETY_ERR ro — This Register provides the Error Status of Bus Safety Comparator of OSPI1 Target Port.
  [31:24] OSPI1_BUS_SAFETY_ERR_DED — This flag signals detection of dual error in Data at this port.Flag is generted for 32 bit segment of Data BusBit 0 - 1'b1 indicates ded on [31:0] bit of Data busBit 1 - 1'b1 indicates ded on [63:32] bit of Data busBit [7:2] - Unused. Set to 1'b0
  [23:16] OSPI1_BUS_SAFETY_ERR_SEC — This flag signals detection of single error in Data at this port. Flag is generted for 32 bit segment of Data BusBit 0 - 1'b1 indicates sec on [31:0] bit of Data busBit 1 - 1'b1 indicates sec on [63:32] bit of Data busBit [7:2] - Unused. Set to 1'b0
  [15:8] OSPI1_BUS_SAFETY_ERR_COMP_CHECK — This is used to verify the proper functioning of fault Injection on all the buses.1'b1 indicates error in the corresponding Bus has been injected successfully. Bit 0 - This is a Bitwise AND of error compares of all command bus signals.Bit 1 - This is a Bitwise AND of error compares of all write bus signals.Bit 2 - This is a Bitwise AND of error compares of all write status bus signals.Bit 3 - This is a Bitwise AND of error compares of all read bus signals.Bits [7:4] are unused.
  [7:0] OSPI1_BUS_SAFETY_ERR_COMP_ERR — 1'b1 indicates error in the corresponding Bus whenever a fault is detected at any bus signalBit 0 - This is a Bitwise OR of error compares of all command bus signals.Bit 1 - This is a Bitwise OR of error compares of all write bus signals.Bit 2 - This is a Bitwise OR of error compares of all write status bus signals.Bit 3 - This is a Bitwise OR of error compares of all read bus signals.Bits [7:4] are unused.
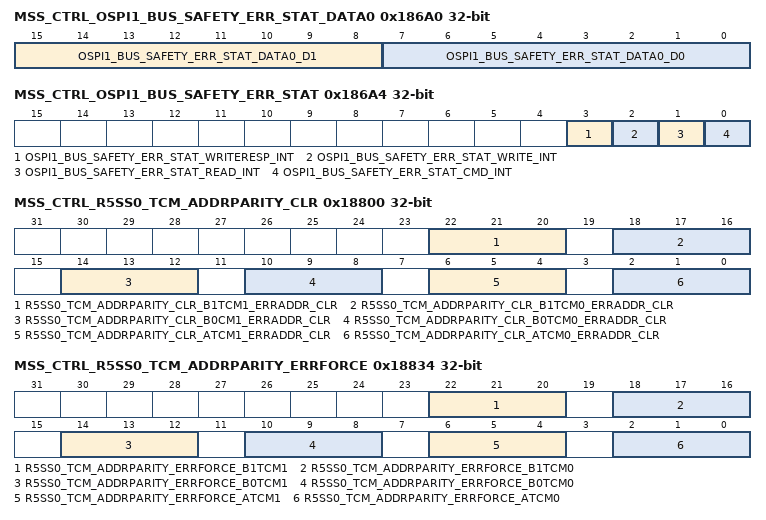
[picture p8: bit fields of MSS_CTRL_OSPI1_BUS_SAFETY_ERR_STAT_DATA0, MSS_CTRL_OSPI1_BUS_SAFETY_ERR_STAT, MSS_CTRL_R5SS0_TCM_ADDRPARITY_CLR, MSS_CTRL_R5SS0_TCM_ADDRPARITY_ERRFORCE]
0x186A0 MSS_CTRL_OSPI1_BUS_SAFETY_ERR_STAT_DATA0 ro — This register Indicates the Error Syndrome of Data errors in Bus Safety Comparator of OSPI1 Target Port.
  [15:8] OSPI1_BUS_SAFETY_ERR_STAT_DATA0_D1 — Read this bitfield for Comparator status for Higher 32 bits [63:32] of data bus at this port. It represent the position of the flipped bit in case of SEC.
  [7:0] OSPI1_BUS_SAFETY_ERR_STAT_DATA0_D0 — Read this bitfield for Comparator status for lower 32 bits [31:0] of data bus at this port. It represent the position of the flipped bit in case of SEC.
0x186A4 MSS_CTRL_OSPI1_BUS_SAFETY_ERR_STAT ro — This register Indicates the Error Syndrome of Command errors in Bus Safety Comparator of OSPI1 Target Port.
  [3] OSPI1_BUS_SAFETY_ERR_STAT_WRITERESP_INT — Read this bitfield for comparator status for Write response bus from interconnect for this port. 1'b1 indicates error on Write Response Bus.
  [2] OSPI1_BUS_SAFETY_ERR_STAT_WRITE_INT — Read this bitfield for comparator status for Write bus from interconnect for this port. 1'b1 at any bit indicates error on Write Bus
  [1] OSPI1_BUS_SAFETY_ERR_STAT_READ_INT — Read this bitfield for comapartor status for read signals at this port. 1'b1 on any of the bits indicates an error on Read bus.
  [0] OSPI1_BUS_SAFETY_ERR_STAT_CMD_INT — Read this bitfield for comparator status for command bus for this port. 1'b1 on any of the bits indicates an error on Command Bus
0x18800 MSS_CTRL_R5SS0_TCM_ADDRPARITY_CLR — This register clears the TCM Address Parity Errors of R5SS0.
  [22:20] R5SS0_TCM_ADDRPARITY_CLR_B1TCM1_ERRADDR_CLR — Write pulse bit field:Writing 3'b111 clears the Address latched after parity error for B1TCM of CR5B
  [18:16] R5SS0_TCM_ADDRPARITY_CLR_B1TCM0_ERRADDR_CLR — Write pulse bit field:Writing 3'b111 clears the Address latched after parity error for B1TCM of CR5A
  [14:12] R5SS0_TCM_ADDRPARITY_CLR_B0CM1_ERRADDR_CLR — Write pulse bit field:Writing 3'b111 clears the Address latched after parity error for B0TCM of CR5B
  [10:8] R5SS0_TCM_ADDRPARITY_CLR_B0TCM0_ERRADDR_CLR — Write pulse bit field:Writing 3'b111 clears the Address latched after parity error for B0TCM of CR5A
  [6:4] R5SS0_TCM_ADDRPARITY_CLR_ATCM1_ERRADDR_CLR — Write pulse bit field:Writing 3'b111 clears the Address latched after parity error for ATCM of CR5B
  [2:0] R5SS0_TCM_ADDRPARITY_CLR_ATCM0_ERRADDR_CLR — Pulse bit-field Writing 3'b111 clears the Address latched after parity error for ATCM of CR5A
0x18804 MSS_CTRL_R5SS0_CORE0_ADDRPARITY_ERR_ATCM ro — This register latches the ATCM Address where the Address Parity Error occurred in R5SS0 CORE0.
  [19:0] R5SS0_CORE0_ADDRPARITY_ERR_ATCM_ADDR — Address lathched when parity error is occurred for ATCM of CR5A
0x18808 MSS_CTRL_R5SS0_CORE1_ADDRPARITY_ERR_ATCM ro — This register latches the ATCM Address where the Address Parity Error occurred in R5SS0 CORE1.
  [19:0] R5SS0_CORE1_ADDRPARITY_ERR_ATCM_ADDR — Address lathched when parity error is occurred for ATCM of CR5B
0x1880C MSS_CTRL_R5SS0_CORE0_ERR_ADDRPARITY_B0TCM ro — This register latches the B0TCM Address where the Address Parity Error occurred in R5SS0 CORE0.
  [19:0] R5SS0_CORE0_ERR_ADDRPARITY_B0TCM_ADDR — Address lathched when parity error is occurred for B0TCM of CR5A
0x18810 MSS_CTRL_R5SS0_CORE1_ERR_ADDRPARITY_B0TCM ro — This register latches the B0TCM Address where the Address Parity Error occurred in R5SS0 CORE1.
  [19:0] R5SS0_CORE1_ERR_ADDRPARITY_B0TCM_ADDR — Address lathched when parity error is occurred for B0TCM of CR5B
0x18814 MSS_CTRL_R5SS0_CORE0_ERR_ADDRPARITY_B1TCM ro — This register latches the B1TCM Address where the Address Parity Error occurred in R5SS0 CORE0.
  [19:0] R5SS0_CORE0_ERR_ADDRPARITY_B1TCM_ADDR — Address lathched when parity error is occurred for B1TCM of CR5A
0x18818 MSS_CTRL_R5SS0_CORE1_ERR_ADDRPARITY_B1TCM ro — This register latches the B1TCM Address where the Address Parity Error occurred in R5SS0 CORE1.
  [19:0] R5SS0_CORE1_ERR_ADDRPARITY_B1TCM_ADDR — Address lathched when parity error is occurred for B1TCM of CR5B
0x18834 MSS_CTRL_R5SS0_TCM_ADDRPARITY_ERRFORCE — This register is used to Inject fault in the TCM Address Parity Error detection logic of R5SS0 .
  [22:20] R5SS0_TCM_ADDRPARITY_ERRFORCE_B1TCM1 — Write pulse bit field:Writing 3'b111 forces a parity error for B1TCM of CR5B
  [18:16] R5SS0_TCM_ADDRPARITY_ERRFORCE_B1TCM0 — Write pulse bit field:Writing 3'b111 forces a parity error for B1TCM of CR5A
  [14:12] R5SS0_TCM_ADDRPARITY_ERRFORCE_B0TCM1 — Write pulse bit field:Writing 3'b111 forces a parity error for B0TCM of CR5B
  [10:8] R5SS0_TCM_ADDRPARITY_ERRFORCE_B0TCM0 — Write pulse bit field:Writing 3'b111 forces a parity error for B0TCM of CR5A
  [6:4] R5SS0_TCM_ADDRPARITY_ERRFORCE_ATCM1 — Write pulse bit field:Writing 3'b111 forces a parity error for ATCM of CR5B
  [2:0] R5SS0_TCM_ADDRPARITY_ERRFORCE_ATCM0 — Write pulse bit field:Writing 3'b111 forces a parity error for ATCM of CR5A
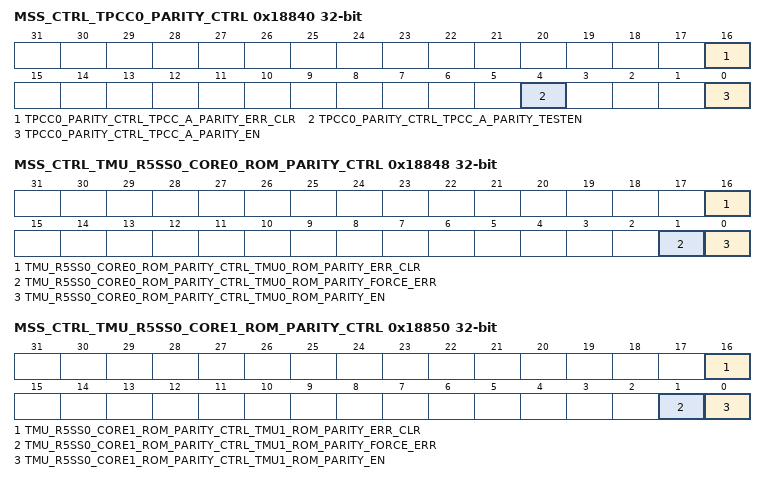
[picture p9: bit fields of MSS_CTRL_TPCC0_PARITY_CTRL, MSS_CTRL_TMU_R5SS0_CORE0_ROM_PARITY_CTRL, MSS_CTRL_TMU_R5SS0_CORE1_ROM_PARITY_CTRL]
0x18840 MSS_CTRL_TPCC0_PARITY_CTRL — This register Controls the Parity Error detection logic of EDMA TPCC0 Memories.
  [16] TPCC0_PARITY_CTRL_TPCC_A_PARITY_ERR_CLR — Write pulse bit field:parity clear bit. Writing 1'b1 will clear the tpcc_a_parity_addr
  [4] TPCC0_PARITY_CTRL_TPCC_A_PARITY_TESTEN — parity test enable for tpcc a
  [0] TPCC0_PARITY_CTRL_TPCC_A_PARITY_EN — Writing 1'b1 enables parity for TPCC_A
0x18844 MSS_CTRL_TPCC0_PARITY_STATUS ro — This register indicates the Address where the Parity Error occurred in TPCC0 Memory.
  [8:0] TPCC0_PARITY_STATUS_TPCC_A_PARITY_ADDR — Address where parity error happened for tpcca
0x18848 MSS_CTRL_TMU_R5SS0_CORE0_ROM_PARITY_CTRL — This register Controls the Parity Error detection logic of TMU R5SS0 CORE0 Memories.
  [16] TMU_R5SS0_CORE0_ROM_PARITY_CTRL_TMU0_ROM_PARITY_ERR_CLR — Write pulse bit field:parity clear bit. Writing 1'b1 will clear the tmu0_rom_parity_err_addr
  [1] TMU_R5SS0_CORE0_ROM_PARITY_CTRL_TMU0_ROM_PARITY_FORCE_ERR — Force parity error on the read interface
  [0] TMU_R5SS0_CORE0_ROM_PARITY_CTRL_TMU0_ROM_PARITY_EN — Writing 1'b1 enables parity for TMU0
0x1884C MSS_CTRL_TMU_R5SS0_CORE0_ROM_PARITY_STATUS ro — This register indicates the Address where the Parity Error occurred in TMU R5SS0 CORE0 ROM.
  [10:0] TMU_R5SS0_CORE0_ROM_PARITY_STATUS_TMU0_ROM_PARITY_ERR_ADDR — Address where parity error happened for tmu0
0x18850 MSS_CTRL_TMU_R5SS0_CORE1_ROM_PARITY_CTRL — This register Controls the Parity Error detection logic of TMU R5SS0 CORE1 Memories.
  [16] TMU_R5SS0_CORE1_ROM_PARITY_CTRL_TMU1_ROM_PARITY_ERR_CLR — Write pulse bit field:parity clear bit. Writing 1'b1 will clear the tmu1_rom_parity_err_addr
  [1] TMU_R5SS0_CORE1_ROM_PARITY_CTRL_TMU1_ROM_PARITY_FORCE_ERR — Force parity error on the read interface
  [0] TMU_R5SS0_CORE1_ROM_PARITY_CTRL_TMU1_ROM_PARITY_EN — Writing 1'b1 enables parity for TMU1
0x18854 MSS_CTRL_TMU_R5SS0_CORE1_ROM_PARITY_STATUS ro — This register indicates the Address where the Parity Error occurred in TMU R5SS0 CORE1 ROM.
  [10:0] TMU_R5SS0_CORE1_ROM_PARITY_STATUS_TMU1_ROM_PARITY_ERR_ADDR — Address where parity error happened for tmu1
